AUTOSAR XML (schema 4-3-0)
package /SeatHeater
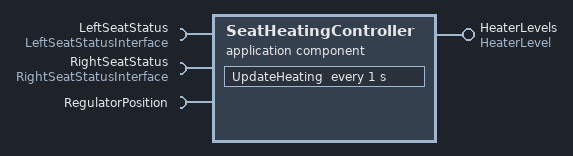
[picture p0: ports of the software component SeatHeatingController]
  application sw component type SeatHeatingController
    require port LeftSeatStatus: nonqueued-receiver-com-spec=PassengerOnLeftSeat, required-interface=LeftSeatStatusInterface
    require port RightSeatStatus: nonqueued-receiver-com-spec=PassengerOnRightSeat, required-interface=RightSeatStatusInterface
    require port RegulatorPosition: nonqueued-receiver-com-spec=Position, required-interface=RegulatorPosition
    provide port HeaterLevels: provided-com-specs=[RightHeatLevel, LeftHeatLevel], provided-interface=HeaterLevel
    behavior SeatHeatingController_InternalBehavior
      events:
        timing event HeatingUpdateEvent: start-on-event=UpdateHeating, period=1
      runnable UpdateHeating
        data-send-points:
          access HeaterLeftLevelAccess: accessed-variable=HeaterLevels.LeftHeatLevel
          access HeaterRightLevelAccess: accessed-variable=HeaterLevels.RightHeatLevel
        data-receive-point-by-values:
          access LeftSeatStatusAccess: accessed-variable=LeftSeatStatus.PassengerOnLeftSeat
          access RightSeatStatusAccess: accessed-variable=RightSeatStatus.PassengerOnRightSeat
          access RegulatorPositionAccess: accessed-variable=RegulatorPosition.Position
  swc implementation SeatHeatingController_Implementation: behavior=SeatHeatingController_InternalBehavior
